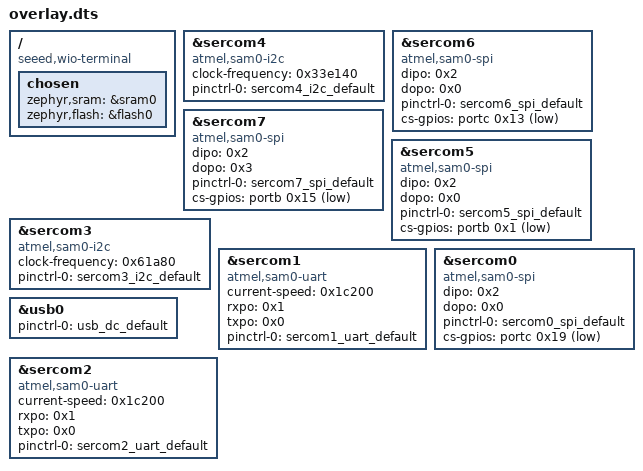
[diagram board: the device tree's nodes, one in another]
/ {
	compatible = "seeed,wio-terminal";
	chosen {
		zephyr,sram = &sram0;
		zephyr,flash = &flash0;
	};
};
&sercom4{
	compatible = "atmel,sam0-i2c";
	status = "okay";
	clock-frequency = < 0x33e140 >;
	#address-cells = < 0x1 >;
	#size-cells = < 0x0 >;
	pinctrl-0 = < &sercom4_i2c_default >;
	pinctrl-names = "default";
};
&sercom6{
	compatible = "atmel,sam0-spi";
	status = "okay";
	#address-cells = < 0x1 >;
	#size-cells = < 0x0 >;
	dipo = < 0x2 >;
	dopo = < 0x0 >;
	pinctrl-0 = < &sercom6_spi_default >;
	pinctrl-names = "default";
	cs-gpios = < &portc 0x13 0x1 >;
};
&sercom7{
	compatible = "atmel,sam0-spi";
	status = "okay";
	#address-cells = < 0x1 >;
	#size-cells = < 0x0 >;
	dipo = < 0x2 >;
	dopo = < 0x3 >;
	pinctrl-0 = < &sercom7_spi_default >;
	pinctrl-names = "default";
	cs-gpios = < &portb 0x15 0x1 >;
};
&sercom5{
	compatible = "atmel,sam0-spi";
	status = "okay";
	#address-cells = < 0x1 >;
	#size-cells = < 0x0 >;
	dipo = < 0x2 >;
	dopo = < 0x0 >;
	pinctrl-0 = < &sercom5_spi_default >;
	pinctrl-names = "default";
	cs-gpios = < &portb 0x1 0x1 >;
};
&sercom3{
	compatible = "atmel,sam0-i2c";
	status = "okay";
	clock-frequency = < 0x61a80 >;
	#address-cells = < 0x1 >;
	#size-cells = < 0x0 >;
	pinctrl-0 = < &sercom3_i2c_default >;
	pinctrl-names = "default";
};
&sercom1{
	compatible = "atmel,sam0-uart";
	status = "okay";
	current-speed = < 0x1c200 >;
	rxpo = < 0x1 >;
	txpo = < 0x0 >;
	pinctrl-0 = < &sercom1_uart_default >;
	pinctrl-names = "default";
};
&sercom0{
	compatible = "atmel,sam0-spi";
	status = "okay";
	#address-cells = < 0x1 >;
	#size-cells = < 0x0 >;
	dipo = < 0x2 >;
	dopo = < 0x0 >;
	pinctrl-0 = < &sercom0_spi_default >;
	pinctrl-names = "default";
	cs-gpios = < &portc 0x19 0x1 >;
};
&usb0{
	status = "okay";
	pinctrl-0 = < &usb_dc_default >;
	pinctrl-names = "default";
};
&sercom2{
	compatible = "atmel,sam0-uart";
	status = "okay";
	current-speed = < 0x1c200 >;
	rxpo = < 0x1 >;
	txpo = < 0x0 >;
	pinctrl-0 = < &sercom2_uart_default >;
	pinctrl-names = "default";
};
